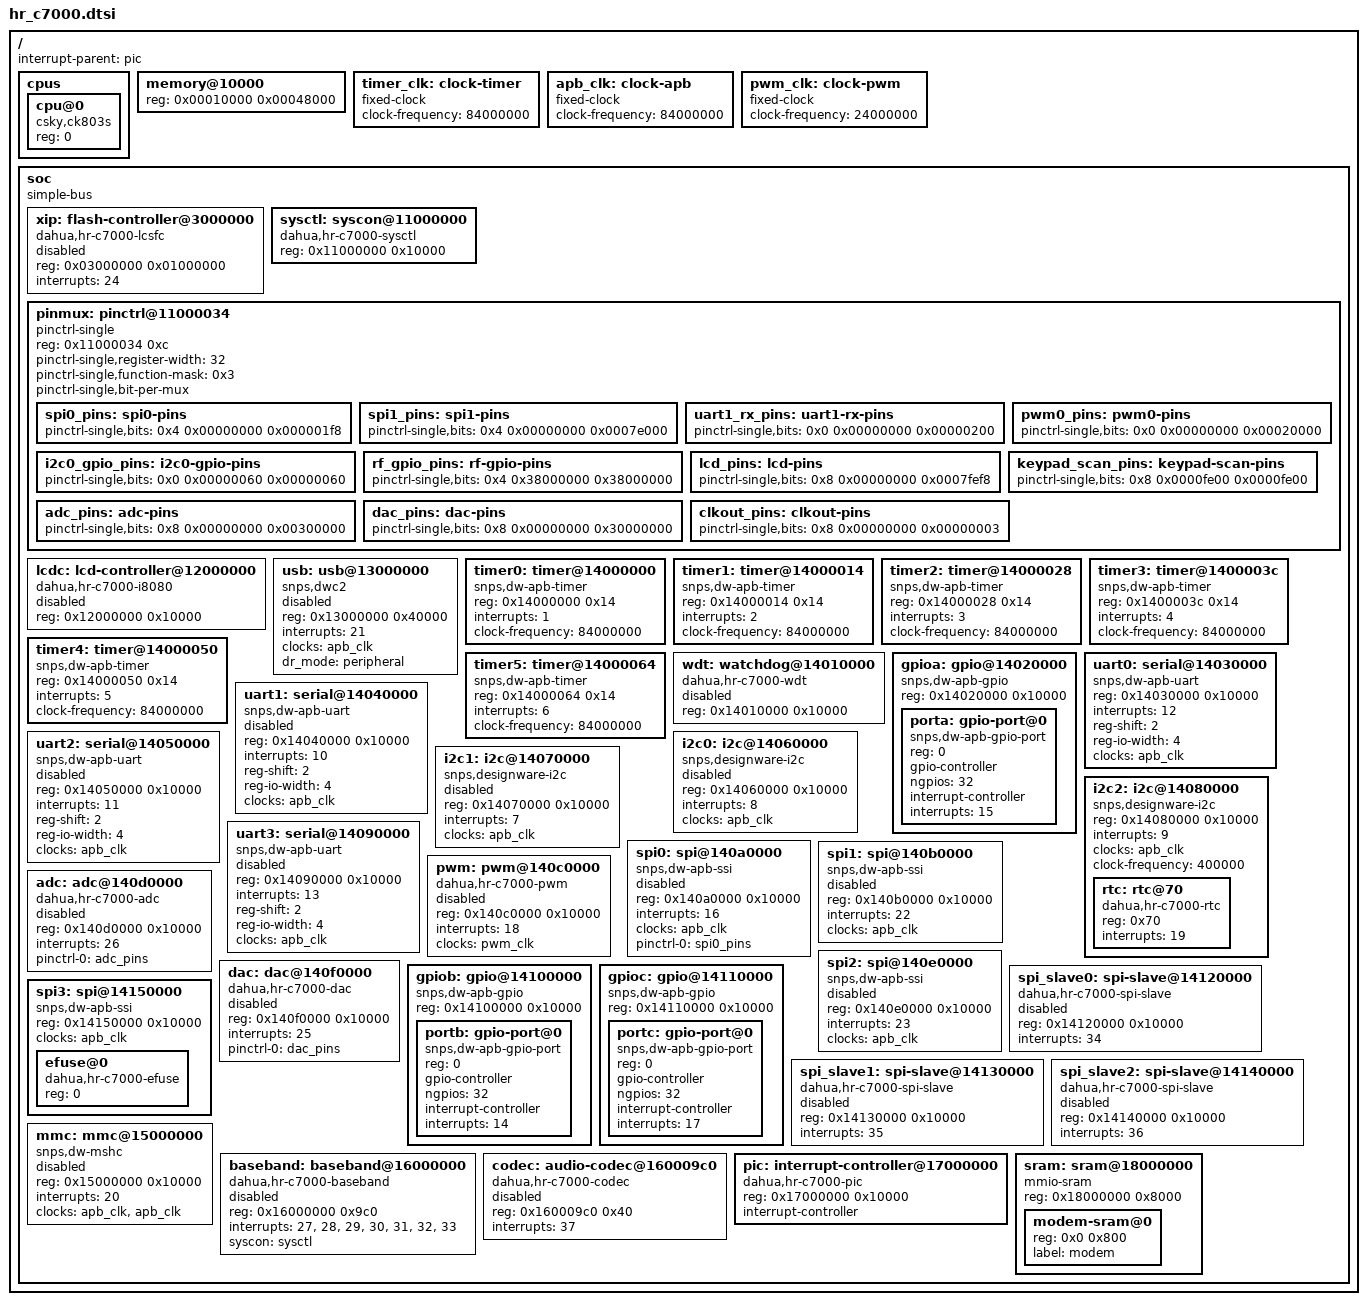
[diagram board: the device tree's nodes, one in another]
/*
 * hr_c7000.dtsi - the Dahua/Hongrui HR_C7000 SoC (C-SKY CK803S core) as used in the
 * Baofeng DM-32UV. SoC-level nodes only; the board is in dm32uv.dts.
 *
 * Hand-maintained. Conventions (specs/README.md, "Evidence rules"): every node and pin carries a
 * comment citing its source. Source tags, as in data/registers/README.md:
 *   [DS]   HR_C7000 Chip User Guide v2.7 (English), section and PDF page. Not redistributed.
 *   [SVD]  data/registers/HR_C7000-DM32.svd (bases, PIC sources, firmware access counts).
 *   [FW]   stock DM32.00.01.048 program image (load base 0x03000000) or its IRAM image
 *          (data/firmware/IRAM_dm32.00.01.048.bin, base 0x00010000), by function/instruction
 *          address; names are the corpus names in meta/functions.json.
 *   [HW]   observed on a real radio (register state only, no per-unit data).
 *   [QEMU] vendor/dm32uv-qemu board model.
 *   [INF]  inferred; treat as a hypothesis.
 *
 * Interrupts: `interrupts` values are PIC SOURCE numbers (DS Table 30, p.168-169). The CPU sees
 * source n as vector n + 32; stock code passes vectors (irq_controller_unmask_and_register_handler
 * @0x0306cf70). Every Table 30 source is level-triggered, active high, so one cell suffices.
 *
 * Compatibles: upstream Linux bindings (Documentation/devicetree/bindings, checked against tag
 * v6.16) wherever the block IS that IP: the SVD and DS identify the timer, GPIO, UART, I2C, SSI,
 * USB and SDIO blocks as Synopsys DesignWare IPs. Blocks with no generic binding get an invented
 * compatible in the "dahua," namespace (the datasheet publisher). "dahua" is NOT a registered
 * vendor prefix (vendor-prefixes.yaml, v6.16); these strings are local to this repository.
 *
 * Clocks: the bus clock rate is set at run time by the clock manager (stock reads it from a RAM
 * variable at 0x0003a60c; uart0_init @0x0301da48, i2c2_master_init_400khz @0x0301dacc) and is not
 * established statically. See the two fixed-clock nodes below for what is known.
 */

/ {
	#address-cells = <1>;
	#size-cells = <1>;
	interrupt-parent = <&pic>;

	cpus {
		#address-cells = <1>;
		#size-cells = <0>;

		/* C-SKY CK803S, ABIv2, no MMU, no FPU [DS ch.2].
		 * "csky" is a registered vendor prefix; upstream documents only the MMU cores
		 * (ck807/ck810/ck860), so this compatible is undocumented. 192 MHz is the datasheet
		 * maximum, not a measured rate, so no clock-frequency is given. */
		cpu@0 {
			device_type = "cpu";
			compatible = "csky,ck803s", "csky,ck803";
			reg = <0>;
		};
	};

	/* IRAM, 288 KB, 0x00010000-0x00057fff [DS memory map; SVD]. Code + data of the stock RTOS
	 * runtime is copied here at boot from flash 0x030bfc20 (specs/ksy/dm32_firmware_image.ksy).
	 * Below it, 0x00000000-0x0000ffff is the ~2 KB mask boot ROM mirrored across 64 KB (read
	 * live; DM-32 RE notes), not RAM, so it is not described. */
	memory@10000 {
		device_type = "memory";
		reg = <0x00010000 0x00048000>;
	};

	/* Timer channel reference clock. INFERRED 84 MHz: a live read of TIMER channel 0 shows
	 * LoadCount 0xcd140 (840000) [HW, SVD TIMER description] and the uC/OS-III tick is 100 Hz
	 * (docs/rtos-and-memory.md). */
	timer_clk: clock-timer {
		compatible = "fixed-clock";
		#clock-cells = <0>;
		clock-frequency = <84000000>;
	};

	/* APB peripheral clock. RATE NOT ESTABLISHED: the 84 MHz here is the timer rate above,
	 * reused as a placeholder so the DesignWare bindings that require a clock are satisfied.
	 * An OpenRTX port booted on hardware reported APB 60 MHz with the stock BOOTLOADER's PLL
	 * setting; the stock application may reprogram it. Measure before trusting any divider
	 * computed from this. */
	apb_clk: clock-apb {
		compatible = "fixed-clock";
		#clock-cells = <0>;
		clock-frequency = <84000000>;
	};

	/* PWM counter clock, 24 MHz: the stock PWM setter @0x0301c1bc divides the constant
	 * 24000000 (movi 0xb71b, rotli 9) by the requested frequency to get the period [FW]. */
	pwm_clk: clock-pwm {
		compatible = "fixed-clock";
		#clock-cells = <0>;
		clock-frequency = <24000000>;
	};

	soc {
		compatible = "simple-bus";
		#address-cells = <1>;
		#size-cells = <1>;
		ranges;

		/* LCSFC: the execute-in-place serial-flash controller. Its window is the 16 MB
		 * "Flash execution space" 0x03000000-0x03ffffff [DS memory map; HR_C7000 v2.2 manual
		 * p.10]; its control registers live in SystemControl (LCSFC_BAUDR +0x30, QUAD_ENABLE
		 * +0x5c, DS 4.4.4.1/4.4.4.3). PIC source 24 [DS Table 30]. No generic binding fits a
		 * memory-mapped XIP controller of this kind. No runtime write path to this flash exists
		 * in stock firmware (DM-32 RE notes). The board puts the GD25Q80 under it. */
		xip: flash-controller@3000000 {
			compatible = "dahua,hr-c7000-lcsfc";
			reg = <0x03000000 0x01000000>;
			interrupts = <24>;
			#address-cells = <1>;
			#size-cells = <0>;
			status = "disabled";
		};

		/* SystemControl: soft reset, clock manager, pad mux, baseband/DMR/FM control, one
		 * 64 KB window [SVD SystemControl; DS 4.1-4.6, 9.2, 10.2, 11.2]. */
		sysctl: syscon@11000000 {
			compatible = "dahua,hr-c7000-sysctl", "syscon";
			reg = <0x11000000 0x10000>;
		};

		/* Pad mux: IO_DIPLEX0/1/2 at SystemControl +0x34/+0x38/+0x3c [DS 4.4.4.4-4.4.4.6,
		 * p.93-105; SVD]. Upstream "pinctrl-single" (pinctrl/pinctrl-single.yaml) with
		 * pinctrl-single,bits = <offset value mask>, offsets relative to 0x11000034. The fields
		 * are mixed 1- and 2-bit wide (all-ones = GPIO, reset value), so function-mask is only
		 * nominal; every group below gives its exact mask. This window overlaps the syscon
		 * above on purpose: it is three words inside it. Each group is a value the STOCK
		 * firmware writes, cited by function. */
		pinmux: pinctrl@11000034 {
			compatible = "pinctrl-single";
			reg = <0x11000034 0xc>;
			#pinctrl-cells = <2>;
			pinctrl-single,register-width = <32>;
			pinctrl-single,function-mask = <0x3>;
			pinctrl-single,bit-per-mux;

			/* SPI0 SCLK/MOSI/MISO to the master (GPIOA 20/21/22); CSN_0 (GPIOA 18) LEFT
			 * on GPIO, so the data-flash chip select is a GPIO: IO_DIPLEX1 &= 0xfffffe07
			 * then gpio(0x12) = 1 [FW spi_m0_init_flash_cs_high @0x0301c94c]. */
			spi0_pins: spi0-pins {
				pinctrl-single,bits = <0x4 0x00000000 0x000001f8>;
			};

			/* SPI1 SCLK/MOSI/MISO (GPIOA 25/26/27): IO_DIPLEX1 &= 0xfff81fff
			 * [FW modem_c7000_param_table_defaults_init @0x0306674c]. Only reached from an
			 * SD-card-over-SPI probe with no caller in the corpus (see &spi1). Conflicts with
			 * the RDA5807M bit-bang on GPIOA 25/26 (dm32uv.dts). */
			spi1_pins: spi1-pins {
				pinctrl-single,bits = <0x4 0x00000000 0x0007e000>;
			};

			/* UART1 RXD only (GPIOA 9). TXD (GPIOA 10) stays GPIO and is driven LOW:
			 * gpio(10) = 0, IO_DIPLEX0 &= ~0x200 [FW gps_uart1_init_9600 @0x0301d96c, checked with
			 * cs_disasm: bclri bit 9 of 0x11000034]. */
			uart1_rx_pins: uart1-rx-pins {
				pinctrl-single,bits = <0x0 0x00000000 0x00000200>;
			};

			/* PWM_0 on GPIOA 15: IO_DIPLEX0 &= 0xfffdffff [FW FUN_0301c1a4], immediately
			 * followed by the channel-0 PWM setup (LCD backlight, dm32uv.dts). */
			pwm0_pins: pwm0-pins {
				pinctrl-single,bits = <0x0 0x00000000 0x00020000>;
			};

			/* I2C0 pads (GPIOA 5/6) forced to GPIO for the bit-banged ALPU-MP bus:
			 * IO_DIPLEX0 |= 0x60 when the bus index at IRAM 0x00033c54 is 0 (it is never
			 * written; only two literal references exist, both reads) [FW IRAM 0x000141c8 =
			 * flash 0x030c3de8]. The index-1 branch (|= 0x180, GPIOA 7/8) is dead. */
			i2c0_gpio_pins: i2c0-gpio-pins {
				pinctrl-single,bits = <0x0 0x00000060 0x00000060>;
			};

			/* RF/LNA switch pads PTB2..PTB4 kept on GPIO: IO_DIPLEX1 |= 0x38000000
			 * [FW hr_c7000_modem_core_clock_and_reset_init @0x0301d5f8]. */
			rf_gpio_pins: rf-gpio-pins {
				pinctrl-single,bits = <0x4 0x38000000 0x38000000>;
			};

			/* LCD bus: CS, RS, WR, DB0..DB7 to the i8080 controller; RD (GPIOC 6) left on
			 * GPIO and parked high. IO_DIPLEX2 &= 0xfff80107 [FW
			 * lcd_controller_power_on_init_sequence @0x03017d4c, literal 0x03017f4c]. */
			lcd_pins: lcd-pins {
				pinctrl-single,bits = <0x8 0x00000000 0x0007fef8>;
			};

			/* Keypad scan state: DB0..DB4 (GPIOC 7..11) handed to GPIO, IO_DIPLEX2 |= 0xfe00
			 * [FW keypad_scan_begin_mux_rows_drive_low @0x03012e14]; undone by
			 * IO_DIPLEX2 &= 0xffff01ff [FW lcd_bus_restore_after_keypad_scan @0x0301cad0].
			 * MUTUALLY EXCLUSIVE with lcd_pins: see the keypad node in dm32uv.dts. */
			keypad_scan_pins: keypad-scan-pins {
				pinctrl-single,bits = <0x8 0x0000fe00 0x0000fe00>;
			};

			/* ADC1_IN (GPIOC 16) and ADC2_IN (GPIOC 17) to the ADC: IO_DIPLEX2 &= ~0x100000,
			 * &= ~0x200000 [FW adc_stop_and_reset @0x0301caec]. */
			adc_pins: adc-pins {
				pinctrl-single,bits = <0x8 0x00000000 0x00300000>;
			};

			/* DAC_VOUT_MCUB/MCUC (GPIOC 24/25) to the DAC: IO_DIPLEX2 &= 0xcfffffff
			 * [FW FUN_0301cc30]. */
			dac_pins: dac-pins {
				pinctrl-single,bits = <0x8 0x00000000 0x30000000>;
			};

			/* CLK_OUT (GPIOC 0) = PLLA clock output: IO_DIPLEX2 &= 0xfffffffc
			 * [FW hr_c7000_modem_core_reset_and_poll_ready @0x030043c8]. Consumer not traced
			 * (an RF-chip reference clock is the obvious candidate) [INF]. */
			clkout_pins: clkout-pins {
				pinctrl-single,bits = <0x8 0x00000000 0x00000003>;
			};
		};

		/* i8080 parallel LCD bus controller: INDEX +0x0 (command), DATA +0x4 [DS 5.3,
		 * p.264-268; SVD i8080]. Stock init: WCFG = 0x303, then sets UNDOC_0x28 bit 0 and
		 * waits for bit 1 [FW lcd_controller_power_on_init_sequence @0x03017d4c]. No interrupt
		 * in Table 30. No upstream binding describes a MIPI-DBI type-B (8080) host. */
		lcdc: lcd-controller@12000000 {
			compatible = "dahua,hr-c7000-i8080";
			reg = <0x12000000 0x10000>;
			#address-cells = <1>;
			#size-cells = <0>;
			status = "disabled";
		};

		/* USB 2.0 OTG, Synopsys DesignWare (GSNPSID 0x4f54270a), device-only with a full-speed
		 * serial transceiver [SVD USB; DS 5.6]. Upstream "snps,dwc2" (usb/dwc2.yaml). PIC
		 * source 21. FW: no direct access, one base literal at 0x0301f178 [SVD] - no known
		 * use on the DM-32, so disabled. */
		usb: usb@13000000 {
			compatible = "snps,dwc2";
			reg = <0x13000000 0x40000>;
			interrupts = <21>;
			clocks = <&apb_clk>;
			clock-names = "otg";
			dr_mode = "peripheral";
			status = "disabled";
		};

		/* Six DesignWare APB timer channels, 0x14 stride [DS 4.8, Register Table 6 p.188-189,
		 * corrected for Timer5/6 per SVD; HW live read]. Upstream "snps,dw-apb-timer"
		 * (timer/snps,dw-apb-timer.yaml) describes ONE channel per node; channel n is PIC
		 * source n+1 [DS Table 30]. Channel 0 is the uC/OS-III tick (source 1, vector 33,
		 * HW-confirmed 2026-10-01); channel 5 is stock's 10 Hz UI tick
		 * (timer_ch4_enable @0x0301d784 via timer_channel_enable_dispatch(5)) [FW, QEMU].
		 * Channels 1-4: use by stock not established. The block-wide registers
		 * (TimersIntStatus/EOI at +0xa0..+0xac) sit outside every channel's reg. */
		timer0: timer@14000000 {
			compatible = "snps,dw-apb-timer";
			reg = <0x14000000 0x14>;
			interrupts = <1>;
			clock-frequency = <84000000>;	/* timer_clk, INFERRED */
		};

		timer1: timer@14000014 {
			compatible = "snps,dw-apb-timer";
			reg = <0x14000014 0x14>;
			interrupts = <2>;
			clock-frequency = <84000000>;
		};

		timer2: timer@14000028 {
			compatible = "snps,dw-apb-timer";
			reg = <0x14000028 0x14>;
			interrupts = <3>;
			clock-frequency = <84000000>;
		};

		timer3: timer@1400003c {
			compatible = "snps,dw-apb-timer";
			reg = <0x1400003c 0x14>;
			interrupts = <4>;
			clock-frequency = <84000000>;
		};

		timer4: timer@14000050 {
			compatible = "snps,dw-apb-timer";
			reg = <0x14000050 0x14>;
			interrupts = <5>;
			clock-frequency = <84000000>;
		};

		timer5: timer@14000064 {
			compatible = "snps,dw-apb-timer";
			reg = <0x14000064 0x14>;
			interrupts = <6>;
			clock-frequency = <84000000>;
		};

		/* Watchdog: lock key 0x5ada7200, feed key 0x55aadd22, ~60 s default, full-chip reset
		 * [DS 4.10, p.212-218; SVD WDG]. Not a DesignWare WDT (custom lock/knock protocol), so
		 * no snps,dw-wdt. Whether stock runs it is NOT established (neither key appears as a
		 * literal in flash or IRAM; tools/include/hr_c7000_regs.h). No Table 30 source. */
		wdt: watchdog@14010000 {
			compatible = "dahua,hr-c7000-wdt";
			reg = <0x14010000 0x10000>;
			status = "disabled";
		};

		/* GPIO banks A/B/C: three Synopsys DesignWare APB GPIO instances, one port each
		 * [DS 5.7, p.377-385; SVD]. Upstream "snps,dw-apb-gpio" (gpio/snps,dw-apb-gpio.yaml).
		 * Firmware pin numbering is bank*32 + bit (gpio_pin_set_output_level @0x0301d184).
		 * Each bank has its own PIC source (A 15, B 14, C 17) [DS Table 30], and stock
		 * registers handlers for all three (vectors 0x2f, 0x2e, 0x31 in FUN_0301d50c) and
		 * uses GPIOB interrupts for the rotary encoder, despite DS 5.7.3 saying only port A
		 * has interrupts [FW]. ONE LAYOUT DIFFERENCE from the standard IP: both-edge
		 * interrupt enable is at +0x78 here (DS 5.7.5.12; stock gpio_pin_configure @0x0300121c
		 * writes +0x78 nine times), not +0x68 where the Linux gpio-dwapb driver expects it. */
		gpioa: gpio@14020000 {
			compatible = "snps,dw-apb-gpio";
			reg = <0x14020000 0x10000>;
			#address-cells = <1>;
			#size-cells = <0>;

			porta: gpio-port@0 {
				compatible = "snps,dw-apb-gpio-port";
				reg = <0>;
				gpio-controller;
				#gpio-cells = <2>;
				ngpios = <32>;
				interrupt-controller;
				#interrupt-cells = <2>;
				interrupts = <15>;
			};
		};

		/* UART0: DesignWare APB UART, 16550-compatible [DS 5.4; SVD]. Upstream
		 * "snps,dw-apb-uart" (serial/snps-dw-apb-uart.yaml). PIC source 12: stock registers
		 * vector 0x2c = 44 [FW uart0_init @0x0301da48]. The CPS programming/console port at
		 * 115200 baud (uart0_init called with 0xe1 << 9 from 0x0305f326) [FW]. */
		uart0: serial@14030000 {
			compatible = "snps,dw-apb-uart";
			reg = <0x14030000 0x10000>;
			interrupts = <12>;
			reg-shift = <2>;
			reg-io-width = <4>;
			clocks = <&apb_clk>;
		};

		/* UART1: PIC source 10 (stock vector 0x2a = 42) [FW gps_uart1_init_9600 @0x0301d96c].
		 * The GPS link on DM-32UV units with the GPS option (dm32uv.dts). */
		uart1: serial@14040000 {
			compatible = "snps,dw-apb-uart";
			reg = <0x14040000 0x10000>;
			interrupts = <10>;
			reg-shift = <2>;
			reg-io-width = <4>;
			clocks = <&apb_clk>;
			status = "disabled";
		};

		/* UART2: PIC source 11. FW: no access found [SVD]. */
		uart2: serial@14050000 {
			compatible = "snps,dw-apb-uart";
			reg = <0x14050000 0x10000>;
			interrupts = <11>;
			reg-shift = <2>;
			reg-io-width = <4>;
			clocks = <&apb_clk>;
			status = "disabled";
		};

		/* I2C0: DesignWare APB I2C [DS 5.1; SVD]. Upstream "snps,designware-i2c". PIC source 8.
		 * FW never touches the controller: the ALPU-MP on its pads is bit-banged (see
		 * i2c0_gpio_pins and dm32uv.dts). */
		i2c0: i2c@14060000 {
			compatible = "snps,designware-i2c";
			reg = <0x14060000 0x10000>;
			interrupts = <8>;
			clocks = <&apb_clk>;
			#address-cells = <1>;
			#size-cells = <0>;
			status = "disabled";
		};

		/* I2C1: PIC source 7. FW: no access found [SVD]. Its pads (GPIOA 7/8) carry the
		 * bit-banged FD6818 bus. */
		i2c1: i2c@14070000 {
			compatible = "snps,designware-i2c";
			reg = <0x14070000 0x10000>;
			interrupts = <7>;
			clocks = <&apb_clk>;
			#address-cells = <1>;
			#size-cells = <0>;
			status = "disabled";
		};

		/* I2C2: dedicated to the on-chip RTC [HR_C7000 v2.2 manual p.10 memory-map note;
		 * DS 4.9]. 400 kHz master: IC_CON = 0x65, FS SCL counts from clk/400000
		 * [FW i2c2_master_init_400khz @0x0301dacc]. PIC source 9. */
		i2c2: i2c@14080000 {
			compatible = "snps,designware-i2c";
			reg = <0x14080000 0x10000>;
			interrupts = <9>;
			clocks = <&apb_clk>;
			clock-frequency = <400000>;
			#address-cells = <1>;
			#size-cells = <0>;

			/* On-chip RTC: an I2C SLAVE at 7-bit 0x70 behind I2C2, not memory-mapped
			 * [DS 4.9, p.200-212; data/registers/README.md "RTC registers"]. Stock reaches it
			 * as IC_TAR = 0xe0 >> 1 [FW rtc_register_read @0x0301c2d4,
			 * rtc_date_validate_and_write @0x0301c498; QEMU hw/misc/dm32_i2c_rtc.c].
			 * 32.768 kHz external crystal. Interrupt: PIC source 19 [DS Table 30]. Not a
			 * discrete chip, so no upstream RTC binding applies. */
			rtc: rtc@70 {
				compatible = "dahua,hr-c7000-rtc";
				reg = <0x70>;
				interrupts = <19>;
			};
		};

		/* UART3: PIC source 13. Not tabulated in DS v2.7; offsets from DRV. FW: no access
		 * found [SVD]. */
		uart3: serial@14090000 {
			compatible = "snps,dw-apb-uart";
			reg = <0x14090000 0x10000>;
			interrupts = <13>;
			reg-shift = <2>;
			reg-io-width = <4>;
			clocks = <&apb_clk>;
			status = "disabled";
		};

		/* SPI master 0: DesignWare APB SSI, FIFO depth 128 [DS 5.2, p.243-264; SVD].
		 * Upstream "snps,dw-apb-ssi" (spi/snps,dw-apb-ssi.yaml). PIC source 16. First entry
		 * of the stock SSI base table at 0x030ada00 [FW]. Carries the 16 MB data flash
		 * (dm32uv.dts). */
		spi0: spi@140a0000 {
			compatible = "snps,dw-apb-ssi";
			reg = <0x140a0000 0x10000>;
			interrupts = <16>;
			clocks = <&apb_clk>;
			#address-cells = <1>;
			#size-cells = <0>;
			pinctrl-names = "default";
			pinctrl-0 = <&spi0_pins>;
			status = "disabled";
		};

		/* SPI master 1: PIC source 22. Second SSI table entry (0x030ada04) [FW]. Its only
		 * configuration path is an SD-card-over-SPI probe (CMD0/CMD8 0x1aa/ACMD41/CMD58
		 * sequence, chip select GPIOA 23) in sdcard_spi_probe_and_init @0x03066ae0,
		 * which has no caller in the corpus [FW]. No attached device known. */
		spi1: spi@140b0000 {
			compatible = "snps,dw-apb-ssi";
			reg = <0x140b0000 0x10000>;
			interrupts = <22>;
			clocks = <&apb_clk>;
			#address-cells = <1>;
			#size-cells = <0>;
			status = "disabled";
		};

		/* PWM: three channels at a 0x20 stride [DS 5.8, p.385-400]. PIC source 18. The SVD
		 * says "FW: no access found"; that sweep only sees movih-built addresses. Stock DOES
		 * use channel 0: 0x0301c1bc builds (0x00a06000 + ch) << 5 = 0x140c0000 + ch*0x20 and
		 * programs a period of 24 MHz / freq and a duty in 1/10000 [FW, cs_disasm]. No generic
		 * binding. Cells: channel, period (ns), flags. */
		pwm: pwm@140c0000 {
			compatible = "dahua,hr-c7000-pwm";
			reg = <0x140c0000 0x10000>;
			interrupts = <18>;
			clocks = <&pwm_clk>;
			#pwm-cells = <3>;
			status = "disabled";
		};

		/* CPU-side 10-bit ADC, channels A..H = index 0..7 [DS 5.9, p.400-423; SVD]. PIC
		 * source 26. Stock reader adc_read_channel_dispatch @0x0301cb44 [FW]. No generic
		 * binding. One io-channel cell = channel index. */
		adc: adc@140d0000 {
			compatible = "dahua,hr-c7000-adc";
			reg = <0x140d0000 0x10000>;
			interrupts = <26>;
			#io-channel-cells = <1>;
			pinctrl-names = "default";
			pinctrl-0 = <&adc_pins>;
			status = "disabled";
		};

		/* SPI2: PIC source 23. Third SSI table entry (0x030ada08) [FW]. Its pads are the LCD
		 * CS/RS/DB0/DB1 pads (IO_DIPLEX2 alternate functions), which the LCD uses. */
		spi2: spi@140e0000 {
			compatible = "snps,dw-apb-ssi";
			reg = <0x140e0000 0x10000>;
			interrupts = <23>;
			clocks = <&apb_clk>;
			#address-cells = <1>;
			#size-cells = <0>;
			status = "disabled";
		};

		/* CPU-side 12-bit DAC, three channels A..C [DS 5.10, p.423-426; SVD]. PIC source 25.
		 * Stock powers it up, zeroes all three outputs and writes 0x6e2 through
		 * dac_channel_write_12bit(4, ...) [FW FUN_0301cc30]. What the outputs drive is not
		 * traced. */
		dac: dac@140f0000 {
			compatible = "dahua,hr-c7000-dac";
			reg = <0x140f0000 0x10000>;
			interrupts = <25>;
			#io-channel-cells = <1>;
			pinctrl-names = "default";
			pinctrl-0 = <&dac_pins>;
			status = "disabled";
		};

		/* GPIO bank B (DS Register Table 21), PIC source 14. */
		gpiob: gpio@14100000 {
			compatible = "snps,dw-apb-gpio";
			reg = <0x14100000 0x10000>;
			#address-cells = <1>;
			#size-cells = <0>;

			portb: gpio-port@0 {
				compatible = "snps,dw-apb-gpio-port";
				reg = <0>;
				gpio-controller;
				#gpio-cells = <2>;
				ngpios = <32>;
				interrupt-controller;
				#interrupt-cells = <2>;
				interrupts = <14>;
			};
		};

		/* GPIO bank C (DS Register Table 22), PIC source 17. */
		gpioc: gpio@14110000 {
			compatible = "snps,dw-apb-gpio";
			reg = <0x14110000 0x10000>;
			#address-cells = <1>;
			#size-cells = <0>;

			portc: gpio-port@0 {
				compatible = "snps,dw-apb-gpio-port";
				reg = <0>;
				gpio-controller;
				#gpio-cells = <2>;
				ngpios = <32>;
				interrupt-controller;
				#interrupt-cells = <2>;
				interrupts = <17>;
			};
		};

		/* SPI slaves 0-2: PIC sources 34-36. Register map INFERRED from the master SSI
		 * [SVD]. FW: no access found. No binding for an SSI in slave role. */
		spi_slave0: spi-slave@14120000 {
			compatible = "dahua,hr-c7000-spi-slave";
			reg = <0x14120000 0x10000>;
			interrupts = <34>;
			status = "disabled";
		};

		spi_slave1: spi-slave@14130000 {
			compatible = "dahua,hr-c7000-spi-slave";
			reg = <0x14130000 0x10000>;
			interrupts = <35>;
			status = "disabled";
		};

		spi_slave2: spi-slave@14140000 {
			compatible = "dahua,hr-c7000-spi-slave";
			reg = <0x14140000 0x10000>;
			interrupts = <36>;
			status = "disabled";
		};

		/* SPI master 3, "EFUSE only" [DS memory map p.134]. Not tabulated in any edition;
		 * stock drives it with the SSI offsets (fourth SSI table entry, 0x030ada0c) [SVD, FW].
		 * No Table 30 source. Stock reads 8 eFuse bytes over it to derive the per-unit
		 * hardware-binding record (tools/src/dm32_patch_tools/scrub_unit_sector.py). */
		spi3: spi@14150000 {
			compatible = "snps,dw-apb-ssi";
			reg = <0x14150000 0x10000>;
			clocks = <&apb_clk>;
			#address-cells = <1>;
			#size-cells = <0>;

			/* On-chip eFuse array, read-only from software's point of view [INF]. No
			 * binding; the bytes are per-unit, so nothing here records them. */
			efuse@0 {
				compatible = "dahua,hr-c7000-efuse";
				reg = <0>;
			};
		};

		/* SD/SDIO host, DesignWare Mobile Storage, FIFO 128 [DS 5.5; SVD]. Upstream
		 * "snps,dw-mshc" (mmc/synopsys-dw-mshc.yaml). PIC source 20. FW: no access found;
		 * no card slot on the DM-32. */
		mmc: mmc@15000000 {
			compatible = "snps,dw-mshc";
			reg = <0x15000000 0x10000>;
			interrupts = <20>;
			clocks = <&apb_clk>, <&apb_clk>;
			clock-names = "biu", "ciu";
			status = "disabled";
		};

		/* Baseband RAM: DMR TX buffer +0x000, RX buffer +0x4b0, then the built-in vocoder's
		 * coded-frame area (0x16000960-0x1600097a) [DS 9.4/10.4/11.4 p.520-521, 555-557, 608;
		 * SVD Modem_Buffer; DS 7.1.1 p.473 "built-in vocoder"]. Interrupts: PCM_rd/wr_data
		 * (vocoder decode/encode) 27/28, System_inter 29, time-slot TX/RX 30/31, RF TX/RX
		 * 32/33 [DS Table 30]. The control registers are in SystemControl. No binding. */
		baseband: baseband@16000000 {
			compatible = "dahua,hr-c7000-baseband";
			reg = <0x16000000 0x9c0>;
			interrupts = <27>, <28>, <29>, <30>, <31>, <32>, <33>;
			interrupt-names = "pcm-rd", "pcm-wr", "system", "slot-tx", "slot-rx",
					  "rf-tx", "rf-rx";
			syscon = <&sysctl>;
			status = "disabled";
		};

		/* Audio codec control, byte-wide registers at 0x160009c0 [DS 6.5, Register Table 26,
		 * p.443-472; SVD CODEC]. PIC source 37 (Codec_interp). No generic binding. */
		codec: audio-codec@160009c0 {
			compatible = "dahua,hr-c7000-codec";
			reg = <0x160009c0 0x40>;
			interrupts = <37>;
			#sound-dai-cells = <0>;
			status = "disabled";
		};

		/* Programmable interrupt controller, 64 sources, 38 assigned [DS 4.7, p.166-187;
		 * Register Table 5 p.170-172; SVD PIC]. The real interrupt controller: the CK803S
		 * core's own VIC at 0xe000e100 is never touched by stock [SVD, HW]. Mask bit = 1
		 * masks; all masked at reset. One cell: the SOURCE number (vector = source + 32). */
		pic: interrupt-controller@17000000 {
			compatible = "dahua,hr-c7000-pic";
			reg = <0x17000000 0x10000>;
			interrupt-controller;
			#interrupt-cells = <1>;
		};

		/* SRAM, 32 KB [DS memory map; SVD]. Upstream "mmio-sram". Stock copies its initialised
		 * data to 0x18000800 (specs/ksy/dm32_firmware_image.ksy); the DemoUV008 linker script
		 * for a sibling product reserves 0x18000000-0x180007ff "for modem" [DRV, INF here]. */
		sram: sram@18000000 {
			compatible = "mmio-sram";
			reg = <0x18000000 0x8000>;
			#address-cells = <1>;
			#size-cells = <1>;
			ranges = <0 0x18000000 0x8000>;

			modem-sram@0 {
				reg = <0x0 0x800>;
				label = "modem";
			};
		};
	};
};
